AUTOSAR XML (schema 314)
package /ComponentType
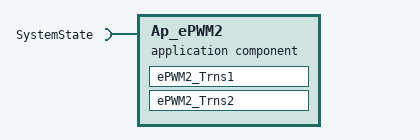
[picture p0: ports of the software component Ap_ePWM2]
  application software component type Ap_ePWM2
    require port SystemState: required-interface=SystemState
  internal behavior Ap_ePWM2_InternalBehavior: component=Ap_ePWM2, port-api-option{enable-take-address=false, indirect-api=false, port=SystemState}
    mode switch event MST_ePWM2_Trns1_0: start-on-event=ePWM2_Trns1, activation=ENTRY, mode=SystemState.Mode.OPERATE
    mode switch event MST_ePWM2_Trns2_0: start-on-event=ePWM2_Trns2, activation=EXIT, mode=SystemState.Mode.OPERATE
    runnable ePWM2_Trns1
    runnable ePWM2_Trns2
  swc implementation Ap_ePWM2_Implementation: behavior=Ap_ePWM2_InternalBehavior
    code-descriptors:
      code Code: type=SRC
